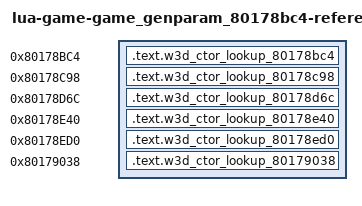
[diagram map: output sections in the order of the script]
/* Generated reference-only placements. All bodies are source-built. */
OUTPUT_FORMAT("elf32-powerpc")
OUTPUT_ARCH(powerpc)
ENTRY(w3d_ctor_lookup_80178bc4)
_SDA_BASE_ = 0x804b2540;
_SDA2_BASE_ = 0x804c2540;
fn_8017892c = 0x8017892c;
fn_8020b680 = 0x8020b680;
lbl_80413018 = 0x80413018;
lbl_80413028 = 0x80413028;
lbl_80413038 = 0x80413038;
lbl_80413048 = 0x80413048;
lbl_80413058 = 0x80413058;
lbl_80413078 = 0x80413078;
w3d_vtable_80412400 = 0x80412400;
w3d_vtable_804124f0 = 0x804124f0;
w3d_vtable_80412540 = 0x80412540;
w3d_vtable_80412590 = 0x80412590;
w3d_vtable_804125e0 = 0x804125e0;
w3d_vtable_80412630 = 0x80412630;
SECTIONS {
  .text.w3d_ctor_lookup_80178bc4 0x80178bc4 : { *(.text.w3d_ctor_lookup_80178bc4) }
  .text.w3d_ctor_lookup_80178c98 0x80178c98 : { *(.text.w3d_ctor_lookup_80178c98) }
  .text.w3d_ctor_lookup_80178d6c 0x80178d6c : { *(.text.w3d_ctor_lookup_80178d6c) }
  .text.w3d_ctor_lookup_80178e40 0x80178e40 : { *(.text.w3d_ctor_lookup_80178e40) }
  .text.w3d_ctor_lookup_80178ed0 0x80178ed0 : { *(.text.w3d_ctor_lookup_80178ed0) }
  .text.w3d_ctor_lookup_80179038 0x80179038 : { *(.text.w3d_ctor_lookup_80179038) }
  /DISCARD/ : { *(.text*) *(.rodata*) *(.data*) *(.bss*) *(.sdata*) *(.sbss*) *(.comment) }
}
